VERSION ""

NS_ :

BS_:
BU_: PEDAL ECU_CMDS F_AXLE IMU LVBMS
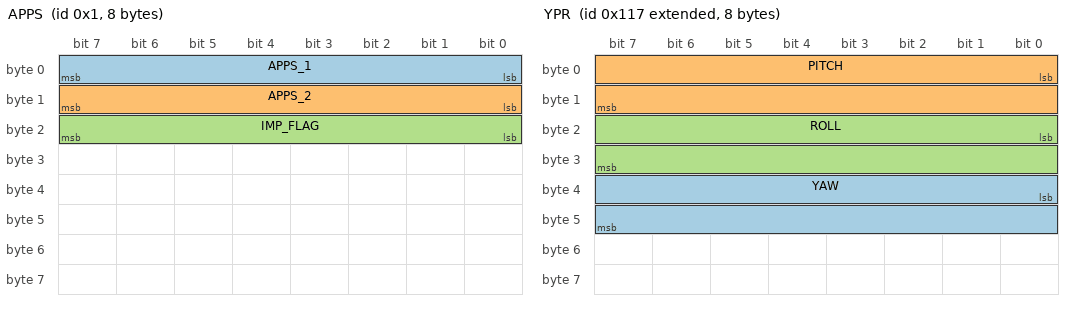
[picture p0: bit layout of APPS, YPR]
BO_ 1 APPS: 8 PEDAL
   SG_ APPS_1 : 0|8@1+ (1,0) [0|255] "" Vector__XXX
   SG_ APPS_2 : 8|8@1+ (1,0) [0|255] "" Vector__XXX
   SG_ IMP_FLAG : 16|8@1+ (1,0) [0|255] "" Vector__XXX

BO_ 4 PEDAL_CMD: 8 ECU_CMDS
   SG_ CMD : 0|8@1+ (1,0) [0|1] "" Vector__XXX
   SG_ ARGS : 8|56@1+ (1,0) [0|1] "" Vector__XXX

BO_ 2 BPPS: 1 PEDAL
   SG_ BPPS : 0|8@1+ (1,0) [0|1] "" Vector__XXX

BO_ 5 STEER: 8 PEDAL
   SG_ ANGLE : 0|16@1- (1,0) [-360|360] "Grad" Vector__XXX

BO_ 277 rWheel: 8 F_AXLE
   SG_ RPM : 0|16@1+ (1,0) [0|1] "" Vector__XXX

BO_ 278 lWheel: 8 F_AXLE
   SG_ RPM : 0|16@1+ (1,0) [0|1] "" Vector__XXX

BO_ 2147483927 YPR: 8 IMU
   SG_ YAW : 32|16@1+ (0.01,0) [0|1] "" Vector__XXX
   SG_ PITCH : 0|16@1+ (0.01,0) [0|1] "" Vector__XXX
   SG_ ROLL : 16|16@1+ (0.01,0) [0|1] "" Vector__XXX

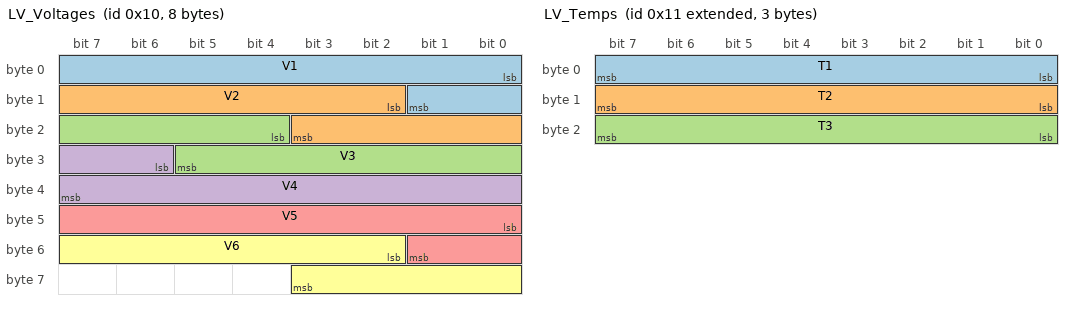
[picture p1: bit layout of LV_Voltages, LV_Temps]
BO_ 16 LV_Voltages: 8 LVBMS
   SG_ V1 : 0|10@1+ (0.01,0) [0|1] "" Vector__XXX
   SG_ V2 : 10|10@1+ (0.01,0) [0|1] "" Vector__XXX
   SG_ V3 : 20|10@1+ (0.01,0) [0|1] "" Vector__XXX
   SG_ V4 : 30|10@1+ (0.01,0) [0|1] "" Vector__XXX
   SG_ V5 : 40|10@1+ (0.01,0) [0|1] "" Vector__XXX
   SG_ V6 : 50|10@1+ (0.01,0) [0|1] "" Vector__XXX

BO_ 2147483665 LV_Temps: 3 LVBMS
   SG_ T1 : 0|8@1+ (1,0) [0|1] "" Vector__XXX
   SG_ T2 : 8|8@1+ (1,0) [0|1] "" Vector__XXX
   SG_ T3 : 16|8@1+ (1,0) [0|1] "" Vector__XXX

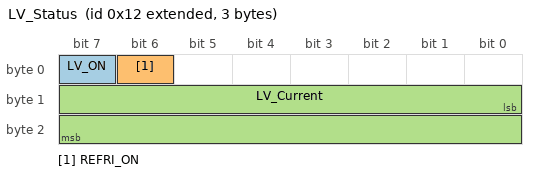
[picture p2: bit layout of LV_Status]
BO_ 2147483666 LV_Status: 3 LVBMS
   SG_ LV_ON : 7|1@1+ (1,0) [0|1] "" Vector__XXX
   SG_ REFRI_ON : 6|1@1+ (1,0) [0|1] "" Vector__XXX
   SG_ LV_Current : 8|16@1+ (1,0) [0|1] "" Vector__XXX

BA_DEF_ BO_ "GenMsgBackgroundColor" STRING ;
BA_DEF_ BO_ "GenMsgForegroundColor" STRING ;
BA_DEF_DEF_ "GenMsgBackgroundColor" "#ffffff";
BA_DEF_DEF_ "GenMsgForegroundColor" "#000000";
